# EFR32BG22 register map
Vendor: Silicon Labs; Series: EFR32; File version: C
Registers are 32-bit, read-write, reset 0x0 unless marked. A register's access mark holds for its fields unless they carry their own. Offsets are from the block's base; [hi:lo] are bit positions.

## EUART0_S — EUART0_S Registers
Base 0x4A030000
0x00 IPVERSION ro
  [31:0] IPVERSION — IP version ID
0x04 EN
  [0] EN — Module enable
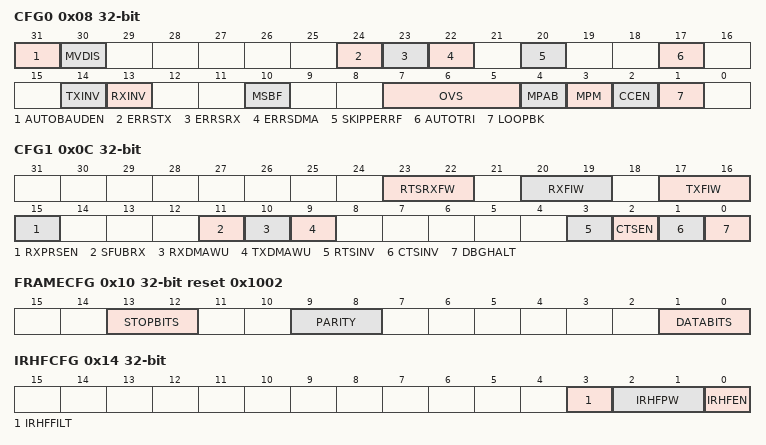
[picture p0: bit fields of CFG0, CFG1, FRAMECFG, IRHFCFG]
0x08 CFG0
  [31] AUTOBAUDEN — AUTOBAUD detection enable
  [30] MVDIS — Majority Vote Disable
  [24] ERRSTX — Disable TX On Error
    0=DISABLE (Received framing and parity errors have no effect on transmitter); 1=ENABLE (Received framing and parity errors disable the transmitter)
  [23] ERRSRX — Disable RX On Error
    0=DISABLE (Framing and parity errors have no effect on receiver); 1=ENABLE (Framing and parity errors disable the receiver)
  [22] ERRSDMA — Halt DMA Read On Error
    0=DISABLE (Framing and parity errors have no effect on DMA requests from the UART); 1=ENABLE (DMA requests from the UART are blocked while the PERR or FERR interrupt flags are set)
  [20] SKIPPERRF — Skip Parity Error Frames
  [17] AUTOTRI — Automatic TX Tristate
    0=DISABLE (The output on UARTn_TX when the transmitter is idle is defined by TXINV); 1=ENABLE (UARTn_TX is tristated whenever the transmitter is idle)
  [14] TXINV — Transmitter output Invert
    0=DISABLE (Output from the transmitter is passed unchanged to UARTn_TX); 1=ENABLE (Output from the transmitter is inverted before it is passed to UARTn_TX)
  [13] RXINV — Receiver Input Invert
    0=DISABLE (Input is passed directly to the receiver); 1=ENABLE (Input is inverted before it is passed to the receiver)
  [10] MSBF — Most Significant Bit First
    0=DISABLE (Data is sent with the least significant bit first); 1=ENABLE (Data is sent with the most significant bit first)
  [7:5] OVS — Oversampling
    0=X16 (16X oversampling); 1=X8 (8X oversampling); 2=X6 (6X oversampling); 3=X4 (4X oversampling); 4=DISABLE (Disable oversampling (for LF operation))
  [4] MPAB — Multi-Processor Address-Bit
  [3] MPM — Multi-Processor Mode
    0=DISABLE (The 9th bit of incoming frames has no special function); 1=ENABLE (An incoming frame with the 9th bit equal to MPAB will be loaded into the RX FIFO regardless of RXBLOCK and will result in the MPAB interrupt flag being set)
  [2] CCEN — Collision Check Enable
    0=DISABLE (Collision check is disabled); 1=ENABLE (Collision check is enabled. The receiver must be enabled for the check to be performed)
  [1] LOOPBK — Loopback Enable
    0=DISABLE (The receiver is connected to and receives data from UARTn_RX); 1=ENABLE (The receiver is connected to and receives data from UARTn_TX)
0x0C CFG1
  [23:22] RTSRXFW — Request-to-send RX FIFO Watermark
    0=ONEFRAME (RTS is set if there is space for at least one more frame in the RX FIFO.); 1=TWOFRAMES (RTS is set if there is space for at least two more frames in the RX FIFO.); 2=THREEFRAMES (RTS is set if there is space for at least three more frames in the RX FIFO.); 3=FOURFRAMES (RTS is set if there is space for four more frames in the RX FIFO.)
  [20:19] RXFIW — RX FIFO Interrupt Watermark
    0=ONEFRAME (RXFL status flag and IF are set when the RX FIFO has at least one frame in it.); 1=TWOFRAMES (RXFL status flag and IF are set when the RX FIFO has at least two frames in it.); 2=THREEFRAMES (RXFL status flag and IF are set when the RX FIFO has at least three frames in it.); 3=FOURFRAMES (RXFL status flag and IF are set when the RX FIFO has four frames in it.)
  [17:16] TXFIW — TX FIFO Interrupt Watermark
    0=ONEFRAME (TXFL status flag and IF are set when the TX FIFO has space for at least one more frame.); 1=TWOFRAMES (TXFL status flag and IF are set when the TX FIFO has space for at least two more frames.); 2=THREEFRAMES (TXFL status flag and IF are set when the TX FIFO has space for at least three more frames.); 3=FOURFRAMES (TXFL status flag and IF are set when the TX FIFO has space for at least four more frames.)
  [15] RXPRSEN — PRS RX Enable
  [11] SFUBRX — Start Frame Unblock Receiver
  [10] RXDMAWU — Receiver DMA Wakeup
  [9] TXDMAWU — Transmitter DMA Wakeup
  [3] RTSINV — Request-to-send Invert Enable
    0=DISABLE (The RTS pin is active low); 1=ENABLE (The RTS pin is active high)
  [2] CTSEN — Clear-to-send Enable
    0=DISABLE (Ignore CTS); 1=ENABLE (Stop transmitting when CTS is inactive)
  [1] CTSINV — Clear-to-send Invert Enable
    0=DISABLE (The CTS pin is active low); 1=ENABLE (The CTS pin is active high)
  [0] DBGHALT — Debug halt
    0=DISABLE (Continue normal UART operation even if core is halted); 1=ENABLE (If core is halted, receive one frame and then halt reception by deactivating RTS. Next frame reception happens when the core is unhalted during single stepping.)
0x10 FRAMECFG reset 0x1002
  [13:12] STOPBITS — Stop-Bit Mode
    0=HALF (The transmitter generates a half stop bit. Stop-bits are not verified by receiver); 1=ONE (One stop bit is generated and verified); 2=ONEANDAHALF (The transmitter generates one and a half stop bit. The receiver verifies the first stop bit); 3=TWO (The transmitter generates two stop bits. The receiver checks the first stop-bit only)
  [9:8] PARITY — Parity-Bit Mode
    0=NONE (Parity bits are not used); 2=EVEN (Even parity are used. Parity bits are automatically generated and checked by hardware.); 3=ODD (Odd parity is used. Parity bits are automatically generated and checked by hardware.)
  [1:0] DATABITS — Data-Bit Mode
    1=SEVEN (Each frame contains 7 data bits); 2=EIGHT (Each frame contains 8 data bits); 3=NINE (Each frame contains 9 data bits)
0x14 IRHFCFG
  [3] IRHFFILT — IrDA RX Filter
    0=DISABLE (No filter enabled); 1=ENABLE (Filter enabled. IrDA pulse must be high for at least 4 consecutive clock cycles to be detected)
  [2:1] IRHFPW — IrDA TX Pulse Width
    0=ONE (IrDA pulse width is 1/16 for OVS=0 and 1/8 for OVS=1); 1=TWO (IrDA pulse width is 2/16 for OVS=0 and 2/8 for OVS=1); 2=THREE (IrDA pulse width is 3/16 for OVS=0 and 3/8 for OVS=1); 3=FOUR (IrDA pulse width is 4/16 for OVS=0 and 4/8 for OVS=1)
  [0] IRHFEN — Enable IrDA Module
0x18 IRLFCFG
  [0] IRLFEN — Pulse Generator/Extender Enable
0x1C TIMINGCFG
  [1:0] TXDELAY — TX Delay Transmission
    0=NONE (Frames are transmitted immediately.); 1=SINGLE (Transmission of new frames is delayed by a single bit period.); 2=DOUBLE (Transmission of new frames is delayed by a two bit periods.); 3=TRIPPLE (Transmission of new frames is delayed by a three bit periods.)
0x20 STARTFRAMECFG
  [8:0] STARTFRAME
0x24 SIGFRAMECFG
  [8:0] SIGFRAME — Signal Frame Value
0x28 CLKDIV
  [22:3] DIV — Fractional Clock Divider
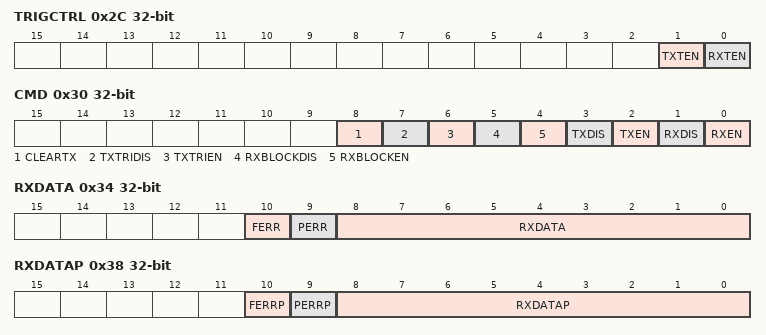
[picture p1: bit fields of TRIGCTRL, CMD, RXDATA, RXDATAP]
0x2C TRIGCTRL
  [1] TXTEN — Transmit Trigger Enable
  [0] RXTEN — Receive Trigger Enable
0x30 CMD wo
  [8] CLEARTX — Clear TX FIFO
  [7] TXTRIDIS — Transmitter Tristate Disable
  [6] TXTRIEN — Transmitter Tristate Enable
  [5] RXBLOCKDIS — Receiver Block Disable
  [4] RXBLOCKEN — Receiver Block Enable
  [3] TXDIS — Transmitter Disable
  [2] TXEN — Transmitter Enable
  [1] RXDIS — Receiver Disable
  [0] RXEN — Receiver Enable
0x34 RXDATA ro
  [10] FERR — Framing Error
  [9] PERR — Parity Error
  [8:0] RXDATA
0x38 RXDATAP ro
  [10] FERRP — Framing Error Peek
  [9] PERRP — Parity Error Peek
  [8:0] RXDATAP — RX Data Peek
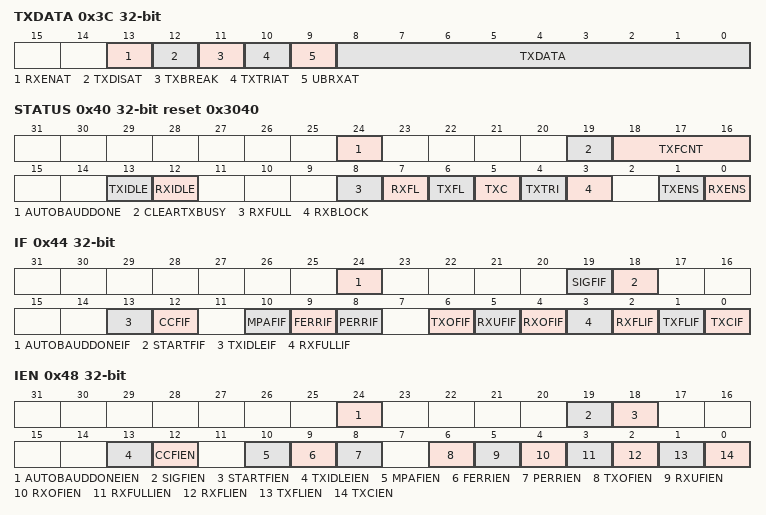
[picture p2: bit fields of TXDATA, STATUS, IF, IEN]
0x3C TXDATA wo
  [13] RXENAT — Enable RXEN After Transmission
  [12] TXDISAT — Clear TXEN After Transmission
  [11] TXBREAK — Transit Data as Break
  [10] TXTRIAT — Set TXTRI After Transmisssion
  [9] UBRXAT — Unblock RX After Transmission
  [8:0] TXDATA
0x40 STATUS ro reset 0x3040
  [24] AUTOBAUDDONE — Auto Baud Rate Detection Completed
  [19] CLEARTXBUSY — TX FIFO Clear Busy
  [18:16] TXFCNT — Valid entries in TX FIFO
  [13] TXIDLE
  [12] RXIDLE
  [8] RXFULL — RX FIFO Full
  [7] RXFL — RX FIFO Level
  [6] TXFL — TX FIFO Level
  [5] TXC — TX Complete
  [4] TXTRI — Transmitter Tristated
  [3] RXBLOCK — Block Incoming Data
  [1] TXENS — Transmitter Enable Status
  [0] RXENS — Receiver Enable Status
0x44 IF
  [24] AUTOBAUDDONEIF — Auto Baud Complete Interrupt Flag
  [19] SIGFIF — Signal Frame Interrupt Flag
  [18] STARTFIF — Start Frame Interrupt Flag
  [13] TXIDLEIF — TX Idle Interrupt Flag
  [12] CCFIF — Collision Check Fail Interrupt Flag
  [10] MPAFIF — Multi-Processor Address Frame Interrupt
  [9] FERRIF — Framing Error Interrupt Flag
  [8] PERRIF — Parity Error Interrupt Flag
  [6] TXOFIF — TX FIFO Overflow Interrupt Flag
  [5] RXUFIF — RX FIFO Underflow Interrupt Flag
  [4] RXOFIF — RX FIFO Overflow Interrupt Flag
  [3] RXFULLIF — RX FIFO Full Interrupt Flag
  [2] RXFLIF — RX FIFO Level Interrupt Flag
  [1] TXFLIF — TX FIFO Level Interrupt Flag
  [0] TXCIF — TX Complete Interrupt Flag
0x48 IEN
  [24] AUTOBAUDDONEIEN — Auto Baud Complete IEN
  [19] SIGFIEN — Signal Frame IEN
  [18] STARTFIEN — Start Frame IEN
  [13] TXIDLEIEN
  [12] CCFIEN — Collision Check Fail IEN
  [10] MPAFIEN — Multi-Processor Addr Frame IEN
  [9] FERRIEN — Framing Error IEN
  [8] PERRIEN — Parity Error IEN
  [6] TXOFIEN — TX FIFO Overflow IEN
  [5] RXUFIEN — RX FIFO Underflow IEN
  [4] RXOFIEN — RX FIFO Overflow IEN
  [3] RXFULLIEN — RX FIFO Full IEN
  [2] RXFLIEN — RX FIFO Level IEN
  [1] TXFLIEN — TX FIFO Level IEN
  [0] TXCIEN — TX Complete IEN
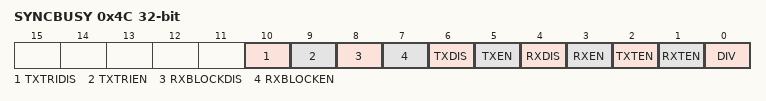
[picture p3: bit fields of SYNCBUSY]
0x4C SYNCBUSY ro
  [10] TXTRIDIS — SYNCBUSY in TXTRIDIS in CMD
  [9] TXTRIEN — SYNCBUSY for TXTRIEN in CMD
  [8] RXBLOCKDIS — SYNCBUSY for RXBLOCKDIS in CMD
  [7] RXBLOCKEN — SYNCBUSY for RXBLOCKEN in CMD
  [6] TXDIS — SYNCBUSY for TXDIS in CMD
  [5] TXEN — SYNCBUSY for TXEN in CMD
  [4] RXDIS — SYNCBUSY for RXDIS in CMD
  [3] RXEN — SYNCBUSY for RXEN in CMD
  [2] TXTEN — SYNCBUSY for TXTEN in TRIGCTRL
  [1] RXTEN — SYNCBUSY for RXTEN in TRIGCTRL
  [0] DIV — SYNCBUSY for DIV in CLKDIV
